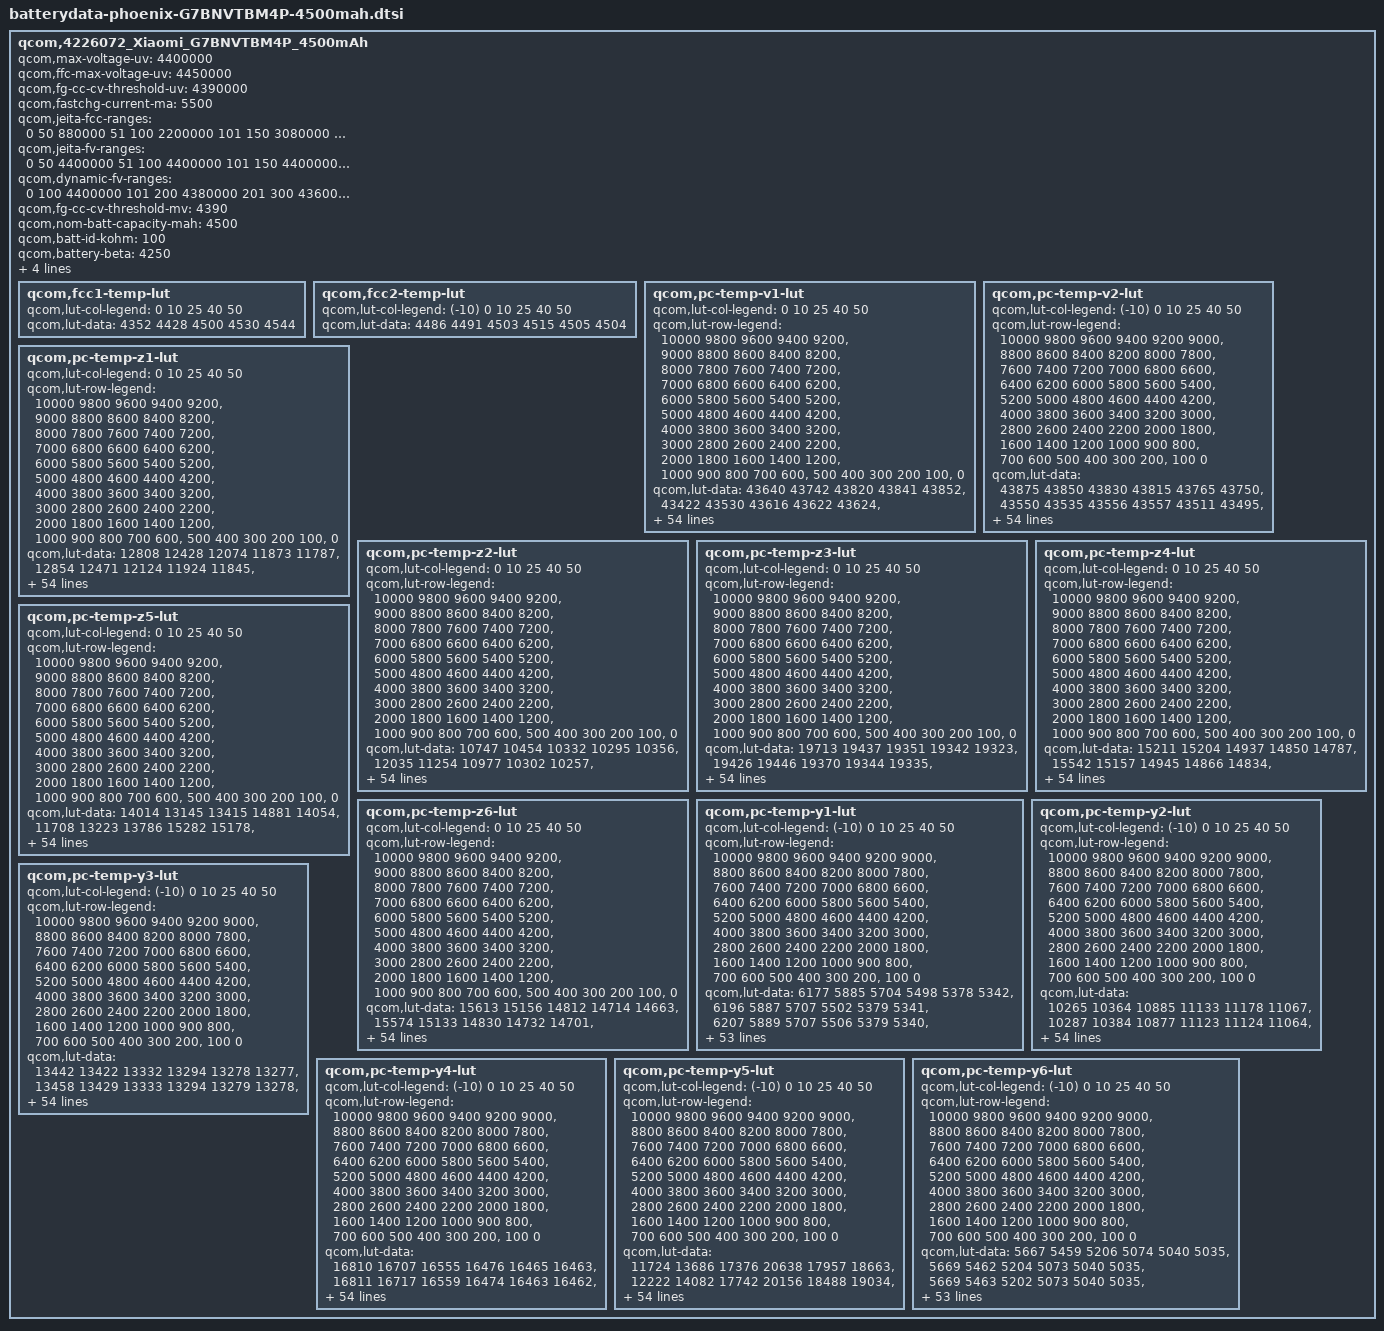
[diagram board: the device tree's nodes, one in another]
qcom,4226072_Xiaomi_G7BNVTBM4P_4500mAh {
    /* 4226072_Xiaomi_G7BNVTBM4P_4500mAh_averaged_MasterSlave_Sept30th2019 */
	qcom,max-voltage-uv = <4400000>;
	qcom,ffc-max-voltage-uv = <4450000>;
	qcom,fg-cc-cv-threshold-uv = <4390000>;
	qcom,fastchg-current-ma = <5500>;
	qcom,jeita-fcc-ranges = <0  50  880000
				51  100  2200000
				101 150  3080000
				151 450  5500000
				451 580  2200000>;
	qcom,jeita-fv-ranges = <0   50  4400000
				51  100  4400000
				101 150  4400000
				151 450  4450000
				451 580  4100000>;
	qcom,dynamic-fv-ranges = <0    100  4400000
				101  200  4380000
				201  300  4360000
				301  400  4340000
				401  500  4340000>;
	qcom,fg-cc-cv-threshold-mv = <4390>;
	qcom,nom-batt-capacity-mah = <4500>;
	qcom,batt-id-kohm = <100>;
	qcom,battery-beta = <4250>;
	qcom,battery-therm-kohm = <100>;
	qcom,battery-type = "G7BNVTBM4P_4500mAh";
	qcom,qg-batt-profile-ver = <100>;
	mi,six-pin-battery;

	qcom,fcc1-temp-lut {
		qcom,lut-col-legend = <0 10 25 40 50>;
		qcom,lut-data = <4352 4428 4500 4530 4544>;
	};

	qcom,fcc2-temp-lut {
		qcom,lut-col-legend = <(-10) 0 10 25 40 50>;
		qcom,lut-data = <4486 4491 4503 4515 4505 4504>;
	};

	qcom,pc-temp-v1-lut {
		qcom,lut-col-legend = <0 10 25 40 50>;
		qcom,lut-row-legend = <10000 9800 9600 9400 9200>,
			<9000 8800 8600 8400 8200>,
			<8000 7800 7600 7400 7200>,
			<7000 6800 6600 6400 6200>,
			<6000 5800 5600 5400 5200>,
			<5000 4800 4600 4400 4200>,
			<4000 3800 3600 3400 3200>,
			<3000 2800 2600 2400 2200>,
			<2000 1800 1600 1400 1200>,
			<1000 900 800 700 600>,
			<500 400 300 200 100>,
			<0>;
		qcom,lut-data = <43640 43742 43820 43841 43852>,
			<43422 43530 43616 43622 43624>,
			<43175 43306 43394 43399 43404>,
			<42915 43069 43166 43176 43182>,
			<42670 42828 42929 42949 42955>,
			<42438 42586 42689 42720 42725>,
			<42211 42344 42451 42488 42495>,
			<41991 42111 42212 42252 42264>,
			<41775 41892 41981 42021 42035>,
			<41566 41679 41756 41793 41808>,
			<41363 41465 41535 41570 41582>,
			<41165 41250 41319 41352 41360>,
			<40972 41045 41105 41137 41141>,
			<40784 40858 40903 40931 40930>,
			<40581 40674 40709 40729 40727>,
			<40345 40470 40518 40533 40532>,
			<40111 40243 40319 40340 40342>,
			<39938 40042 40124 40152 40157>,
			<39802 39899 39954 39976 39982>,
			<39668 39771 39813 39823 39827>,
			<39531 39595 39654 39663 39667>,
			<39387 39345 39413 39446 39459>,
			<39210 39114 39144 39190 39203>,
			<38965 38952 38963 38993 39000>,
			<38758 38817 38839 38854 38856>,
			<38656 38713 38731 38736 38734>,
			<38585 38631 38630 38624 38620>,
			<38522 38560 38539 38521 38516>,
			<38464 38485 38453 38429 38423>,
			<38412 38414 38372 38344 38336>,
			<38362 38351 38299 38268 38258>,
			<38315 38294 38235 38198 38186>,
			<38272 38243 38179 38136 38122>,
			<38235 38197 38129 38079 38060>,
			<38202 38158 38086 38030 38005>,
			<38170 38120 38044 37982 37950>,
			<38142 38088 38004 37931 37889>,
			<38106 38052 37962 37877 37825>,
			<38047 37993 37903 37809 37748>,
			<37962 37904 37816 37722 37655>,
			<37866 37802 37715 37620 37550>,
			<37749 37688 37603 37509 37438>,
			<37613 37554 37474 37381 37310>,
			<37449 37388 37310 37220 37143>,
			<37302 37239 37166 37081 37012>,
			<37213 37142 37070 36993 36935>,
			<37184 37119 37043 36968 36911>,
			<37166 37098 37029 36949 36893>,
			<37147 37080 37012 36932 36875>,
			<37109 37045 36973 36884 36817>,
			<36927 36846 36755 36642 36546>,
			<36488 36410 36323 36210 36109>,
			<35916 35838 35748 35643 35536>,
			<35138 35054 34964 34858 34753>,
			<33901 33819 33742 33654 33539>,
			<30000 30000 30000 30000 30000>;
	};

	qcom,pc-temp-v2-lut {
		qcom,lut-col-legend = <(-10) 0 10 25 40 50>;
		qcom,lut-row-legend = <10000 9800 9600 9400 9200 9000>,
			<8800 8600 8400 8200 8000 7800>,
			<7600 7400 7200 7000 6800 6600>,
			<6400 6200 6000 5800 5600 5400>,
			<5200 5000 4800 4600 4400 4200>,
			<4000 3800 3600 3400 3200 3000>,
			<2800 2600 2400 2200 2000 1800>,
			<1600 1400 1200 1000 900 800>,
			<700 600 500 400 300 200>,
			<100 0>;
		qcom,lut-data = <43875 43850 43830 43815 43765 43750>,
			<43550 43535 43556 43557 43511 43495>,
			<43246 43239 43292 43305 43263 43247>,
			<42968 42966 43037 43060 43022 43006>,
			<42714 42715 42793 42823 42789 42775>,
			<42469 42470 42552 42587 42557 42544>,
			<42227 42225 42314 42352 42323 42311>,
			<41991 41984 42078 42118 42089 42078>,
			<41759 41746 41847 41888 41860 41849>,
			<41530 41507 41620 41662 41633 41622>,
			<41312 41285 41398 41438 41409 41398>,
			<41121 41093 41186 41217 41189 41178>,
			<40938 40912 40978 40999 40973 40963>,
			<40724 40704 40771 40793 40766 40756>,
			<40473 40469 40565 40596 40567 40553>,
			<40205 40233 40361 40400 40372 40359>,
			<39903 40007 40160 40194 40178 40173>,
			<39599 39788 39963 39993 39991 39994>,
			<39387 39583 39771 39822 39821 39825>,
			<39239 39390 39585 39678 39673 39670>,
			<39101 39202 39391 39512 39505 39497>,
			<38953 39008 39167 39271 39270 39266>,
			<38805 38820 38942 39013 39018 39019>,
			<38654 38663 38767 38822 38829 38832>,
			<38494 38528 38624 38667 38678 38681>,
			<38358 38405 38498 38536 38549 38552>,
			<38264 38281 38385 38423 38436 38438>,
			<38188 38169 38284 38324 38336 38337>,
			<38119 38089 38192 38234 38244 38244>,
			<38056 38030 38107 38151 38159 38157>,
			<38000 37981 38031 38075 38082 38079>,
			<37949 37936 37957 38003 38014 38011>,
			<37901 37895 37892 37937 37951 37947>,
			<37854 37859 37846 37876 37886 37879>,
			<37808 37829 37814 37822 37822 37809>,
			<37762 37795 37779 37765 37749 37728>,
			<37713 37751 37740 37702 37655 37619>,
			<37662 37697 37696 37634 37552 37500>,
			<37604 37637 37638 37561 37464 37407>,
			<37540 37568 37563 37483 37387 37332>,
			<37466 37487 37474 37396 37306 37252>,
			<37369 37381 37366 37298 37217 37160>,
			<37255 37253 37241 37186 37114 37053>,
			<37143 37103 37094 37047 36972 36913>,
			<37044 36963 36963 36928 36862 36801>,
			<36963 36870 36890 36871 36816 36761>,
			<36925 36835 36866 36860 36803 36753>,
			<36885 36802 36844 36840 36790 36739>,
			<36837 36755 36808 36813 36768 36711>,
			<36762 36674 36733 36736 36690 36619>,
			<36577 36475 36510 36463 36397 36289>,
			<36182 36065 36016 35953 35905 35790>,
			<35582 35458 35364 35300 35268 35139>,
			<34732 34607 34479 34393 34394 34261>,
			<33365 33219 33123 33054 33081 32922>,
			<28583 28570 28114 28120 28771 28597>;
	};

	qcom,pc-temp-z1-lut {
		qcom,lut-col-legend = <0 10 25 40 50>;
		qcom,lut-row-legend = <10000 9800 9600 9400 9200>,
			<9000 8800 8600 8400 8200>,
			<8000 7800 7600 7400 7200>,
			<7000 6800 6600 6400 6200>,
			<6000 5800 5600 5400 5200>,
			<5000 4800 4600 4400 4200>,
			<4000 3800 3600 3400 3200>,
			<3000 2800 2600 2400 2200>,
			<2000 1800 1600 1400 1200>,
			<1000 900 800 700 600>,
			<500 400 300 200 100>,
			<0>;
		qcom,lut-data = <12808 12428 12074 11873 11787>,
			<12854 12471 12124 11924 11845>,
			<12866 12489 12146 11939 11859>,
			<12869 12487 12150 11943 11865>,
			<12865 12482 12146 11941 11866>,
			<12856 12478 12142 11938 11866>,
			<12850 12471 12137 11935 11865>,
			<12853 12465 12133 11932 11865>,
			<12861 12459 12130 11931 11864>,
			<12862 12452 12126 11930 11865>,
			<12845 12447 12124 11930 11866>,
			<12822 12438 12123 11930 11866>,
			<12807 12431 12121 11932 11866>,
			<12791 12425 12119 11932 11866>,
			<12775 12416 12116 11929 11866>,
			<12756 12409 12113 11927 11866>,
			<12742 12401 12112 11927 11866>,
			<12743 12398 12111 11928 11867>,
			<12755 12403 12111 11929 11868>,
			<12763 12413 12115 11931 11869>,
			<12763 12417 12119 11932 11870>,
			<12762 12421 12122 11932 11871>,
			<12764 12423 12124 11932 11871>,
			<12773 12423 12126 11932 11872>,
			<12781 12422 12128 11935 11874>,
			<12783 12424 12130 11938 11877>,
			<12785 12430 12133 11942 11880>,
			<12784 12436 12138 11945 11883>,
			<12781 12438 12142 11948 11886>,
			<12778 12439 12145 11952 11889>,
			<12782 12439 12149 11955 11892>,
			<12796 12438 12152 11959 11895>,
			<12804 12438 12154 11964 11898>,
			<12805 12442 12158 11968 11901>,
			<12805 12451 12163 11972 11906>,
			<12810 12459 12169 11976 11910>,
			<12824 12466 12173 11980 11913>,
			<12838 12474 12177 11984 11916>,
			<12851 12483 12181 11989 11919>,
			<12863 12494 12187 11993 11922>,
			<12871 12500 12192 11998 11924>,
			<12877 12502 12196 12000 11927>,
			<12879 12503 12199 12003 11930>,
			<12878 12506 12202 12004 11931>,
			<12891 12512 12206 12006 11932>,
			<12888 12517 12210 12010 11933>,
			<12902 12510 12203 12008 11934>,
			<12896 12526 12217 12008 11935>,
			<12890 12514 12223 12012 11938>,
			<12888 12512 12222 12016 11942>,
			<12896 12523 12222 12022 11946>,
			<12917 12534 12245 12030 11952>,
			<12925 12542 12242 12036 11959>,
			<12932 12567 12252 12045 11970>,
			<12932 12567 12252 12045 11970>,
			<12932 12567 12252 12045 11970>;
	};

	qcom,pc-temp-z2-lut {
		qcom,lut-col-legend = <0 10 25 40 50>;
		qcom,lut-row-legend = <10000 9800 9600 9400 9200>,
			<9000 8800 8600 8400 8200>,
			<8000 7800 7600 7400 7200>,
			<7000 6800 6600 6400 6200>,
			<6000 5800 5600 5400 5200>,
			<5000 4800 4600 4400 4200>,
			<4000 3800 3600 3400 3200>,
			<3000 2800 2600 2400 2200>,
			<2000 1800 1600 1400 1200>,
			<1000 900 800 700 600>,
			<500 400 300 200 100>,
			<0>;
		qcom,lut-data = <10747 10454 10332 10295 10356>,
			<12035 11254 10977 10302 10257>,
			<11377 11491 11701 10333 10304>,
			<10414 11301 11844 10407 10339>,
			<10189 11007 11692 11167 10328>,
			<10174 10722 11464 12039 10309>,
			<10166 10410 11026 11823 10293>,
			<10160 10287 10503 10810 10249>,
			<10155 10353 10369 10358 10217>,
			<10154 10424 10351 10737 10207>,
			<10158 10403 10344 11128 10199>,
			<10166 10321 10351 11246 10200>,
			<10198 10285 10371 11595 10208>,
			<10269 10449 10466 11795 10214>,
			<10301 10680 10882 11846 10224>,
			<10266 10683 11187 11904 10236>,
			<10221 10490 11223 11983 10242>,
			<10221 10362 11242 12080 10257>,
			<10251 10377 11170 12062 10273>,
			<10277 10402 10730 11211 10302>,
			<10289 10408 10424 10364 10347>,
			<10298 10409 10450 10361 10419>,
			<10299 10408 10497 10482 10536>,
			<10293 10398 10503 10522 10619>,
			<10289 10379 10476 10466 10670>,
			<10290 10374 10456 10411 10700>,
			<10295 10381 10459 10418 10651>,
			<10299 10388 10466 10440 10489>,
			<10306 10387 10465 10441 10367>,
			<10313 10386 10451 10373 10245>,
			<10321 10387 10440 10302 10154>,
			<10332 10393 10440 10277 10152>,
			<10343 10402 10440 10261 10158>,
			<10357 10413 10443 10259 10169>,
			<10372 10428 10462 10274 10211>,
			<10386 10441 10483 10297 10268>,
			<10399 10450 10497 10335 10323>,
			<10412 10461 10512 10388 10381>,
			<10425 10477 10533 10426 10419>,
			<10439 10500 10565 10455 10447>,
			<10452 10511 10586 10471 10461>,
			<10461 10513 10584 10471 10451>,
			<10477 10516 10580 10466 10431>,
			<10510 10529 10592 10457 10417>,
			<10732 10661 10625 10457 10400>,
			<10904 10730 10649 10477 10394>,
			<10942 10745 10635 10508 10385>,
			<11078 10756 10638 10486 10394>,
			<11243 10780 10620 10524 10475>,
			<11235 10785 10669 10583 10575>,
			<11217 10889 10753 10476 10370>,
			<11047 10885 10729 10338 10190>,
			<10878 10897 10625 10849 10140>,
			<10658 10857 10599 10243 10085>,
			<10658 10857 10599 10243 10085>,
			<10658 10857 10599 10243 10085>;
	};

	qcom,pc-temp-z3-lut {
		qcom,lut-col-legend = <0 10 25 40 50>;
		qcom,lut-row-legend = <10000 9800 9600 9400 9200>,
			<9000 8800 8600 8400 8200>,
			<8000 7800 7600 7400 7200>,
			<7000 6800 6600 6400 6200>,
			<6000 5800 5600 5400 5200>,
			<5000 4800 4600 4400 4200>,
			<4000 3800 3600 3400 3200>,
			<3000 2800 2600 2400 2200>,
			<2000 1800 1600 1400 1200>,
			<1000 900 800 700 600>,
			<500 400 300 200 100>,
			<0>;
		qcom,lut-data = <19713 19437 19351 19342 19323>,
			<19426 19446 19370 19344 19335>,
			<19524 19464 19395 19364 19353>,
			<19668 19508 19419 19382 19369>,
			<19704 19550 19447 19402 19377>,
			<19709 19556 19462 19417 19383>,
			<19711 19557 19457 19414 19384>,
			<19705 19559 19448 19401 19385>,
			<19692 19558 19444 19395 19384>,
			<19680 19554 19442 19402 19382>,
			<19669 19549 19440 19410 19380>,
			<19662 19539 19436 19411 19378>,
			<19667 19534 19431 19412 19376>,
			<19683 19539 19432 19412 19374>,
			<19689 19545 19445 19409 19369>,
			<19679 19544 19453 19406 19362>,
			<19662 19530 19453 19403 19359>,
			<19647 19515 19450 19400 19358>,
			<19631 19500 19444 19394 19355>,
			<19623 19487 19422 19374 19349>,
			<19625 19488 19407 19357 19343>,
			<19631 19512 19413 19359 19345>,
			<19639 19530 19424 19368 19353>,
			<19653 19525 19424 19371 19361>,
			<19662 19514 19411 19364 19371>,
			<19659 19509 19402 19358 19380>,
			<19651 19507 19409 19369 19386>,
			<19643 19506 19422 19396 19396>,
			<19635 19510 19431 19404 19399>,
			<19628 19519 19439 19401 19393>,
			<19623 19521 19443 19397 19384>,
			<19620 19519 19441 19393 19378>,
			<19616 19517 19436 19388 19372>,
			<19611 19514 19431 19382 19365>,
			<19606 19511 19426 19376 19356>,
			<19603 19508 19422 19370 19350>,
			<19600 19504 19417 19366 19349>,
			<19597 19500 19413 19363 19348>,
			<19596 19497 19410 19361 19348>,
			<19593 19494 19408 19360 19348>,
			<19590 19490 19405 19359 19348>,
			<19583 19484 19400 19359 19349>,
			<19576 19478 19395 19358 19351>,
			<19567 19475 19395 19360 19357>,
			<19511 19451 19385 19359 19356>,
			<19461 19437 19376 19349 19348>,
			<19444 19422 19376 19338 19336>,
			<19381 19421 19361 19338 19330>,
			<19322 19416 19360 19333 19321>,
			<19316 19412 19355 19331 19315>,
			<19322 19400 19350 19347 19344>,
			<19321 19393 19347 19355 19351>,
			<19319 19351 19356 19310 19351>,
			<19319 19342 19355 19359 19355>,
			<19319 19342 19355 19359 19355>,
			<19319 19342 19355 19359 19355>;
	};

	qcom,pc-temp-z4-lut {
		qcom,lut-col-legend = <0 10 25 40 50>;
		qcom,lut-row-legend = <10000 9800 9600 9400 9200>,
			<9000 8800 8600 8400 8200>,
			<8000 7800 7600 7400 7200>,
			<7000 6800 6600 6400 6200>,
			<6000 5800 5600 5400 5200>,
			<5000 4800 4600 4400 4200>,
			<4000 3800 3600 3400 3200>,
			<3000 2800 2600 2400 2200>,
			<2000 1800 1600 1400 1200>,
			<1000 900 800 700 600>,
			<500 400 300 200 100>,
			<0>;
		qcom,lut-data = <15211 15204 14937 14850 14787>,
			<15542 15157 14945 14866 14834>,
			<15447 15095 14910 14857 14829>,
			<15276 15004 14871 14842 14821>,
			<15158 14918 14821 14796 14807>,
			<15068 14877 14789 14750 14787>,
			<14999 14853 14782 14746 14770>,
			<14952 14826 14777 14751 14757>,
			<14916 14788 14768 14752 14744>,
			<14887 14757 14750 14725 14731>,
			<14866 14748 14733 14693 14719>,
			<14843 14744 14723 14680 14712>,
			<14803 14738 14714 14665 14707>,
			<14747 14708 14699 14656 14703>,
			<14725 14673 14670 14648 14700>,
			<14742 14673 14649 14642 14697>,
			<14764 14703 14643 14639 14693>,
			<14765 14723 14640 14636 14688>,
			<14754 14716 14640 14636 14683>,
			<14743 14705 14651 14648 14679>,
			<14732 14708 14669 14669 14677>,
			<14723 14749 14719 14708 14696>,
			<14729 14790 14786 14766 14756>,
			<14792 14812 14806 14789 14783>,
			<14845 14829 14812 14793 14770>,
			<14843 14830 14814 14794 14751>,
			<14831 14812 14798 14777 14733>,
			<14819 14789 14765 14732 14710>,
			<14805 14769 14741 14709 14699>,
			<14790 14748 14721 14702 14695>,
			<14777 14735 14708 14696 14693>,
			<14764 14726 14702 14691 14689>,
			<14753 14720 14698 14687 14685>,
			<14743 14716 14695 14685 14682>,
			<14736 14714 14693 14683 14680>,
			<14729 14711 14692 14682 14679>,
			<14722 14707 14690 14682 14680>,
			<14718 14705 14689 14683 14681>,
			<14718 14706 14690 14685 14684>,
			<14718 14709 14695 14692 14692>,
			<14718 14710 14699 14697 14697>,
			<14716 14706 14695 14691 14690>,
			<14712 14701 14690 14683 14681>,
			<14707 14697 14688 14684 14684>,
			<14699 14683 14681 14675 14676>,
			<14716 14672 14669 14664 14656>,
			<14730 14678 14660 14665 14657>,
			<14795 14671 14664 14651 14649>,
			<14856 14670 14654 14637 14637>,
			<14861 14672 14656 14632 14632>,
			<14854 14692 14679 14647 14644>,
			<14869 14709 14692 14651 14650>,
			<14880 14760 14685 14703 14655>,
			<14888 14774 14690 14655 14653>,
			<14888 14774 14690 14655 14653>,
			<14888 14774 14690 14655 14653>;
	};

	qcom,pc-temp-z5-lut {
		qcom,lut-col-legend = <0 10 25 40 50>;
		qcom,lut-row-legend = <10000 9800 9600 9400 9200>,
			<9000 8800 8600 8400 8200>,
			<8000 7800 7600 7400 7200>,
			<7000 6800 6600 6400 6200>,
			<6000 5800 5600 5400 5200>,
			<5000 4800 4600 4400 4200>,
			<4000 3800 3600 3400 3200>,
			<3000 2800 2600 2400 2200>,
			<2000 1800 1600 1400 1200>,
			<1000 900 800 700 600>,
			<500 400 300 200 100>,
			<0>;
		qcom,lut-data = <14014 13145 13415 14881 14054>,
			<11708 13223 13786 15282 15178>,
			<12922 13461 14612 16708 16823>,
			<14963 14601 15761 18189 18427>,
			<16109 16256 17687 20060 19273>,
			<16847 17757 19158 21539 19930>,
			<17286 19340 19655 21405 20387>,
			<17408 20462 19997 20508 20723>,
			<17477 21129 20482 20294 21068>,
			<17593 21674 21152 24126 21539>,
			<17863 22160 21911 28275 22120>,
			<18348 22720 22661 29120 22788>,
			<20007 23659 23593 30310 23599>,
			<23496 27225 25474 31883 23950>,
			<25443 31507 29900 34241 23536>,
			<25823 31751 33843 36580 23003>,
			<25939 28990 36080 38102 23340>,
			<25556 26426 37660 39361 24832>,
			<24466 25042 37160 39382 25727>,
			<23855 24054 32567 33413 25852>,
			<26098 26299 29333 27401 25894>,
			<31014 41133 31330 27005 26063>,
			<36242 52201 34705 27134 26288>,
			<43241 45706 34000 26702 26194>,
			<47788 32512 25575 21763 23585>,
			<44940 26830 19740 17189 20882>,
			<37505 24863 20161 18466 21872>,
			<32764 23963 21321 22345 25112>,
			<30373 25104 23253 25043 26731>,
			<28971 28250 27524 26561 27144>,
			<28991 30860 31487 27908 27417>,
			<29595 33080 33899 29579 27821>,
			<30241 34964 35771 31226 28413>,
			<30770 36341 36946 31964 28592>,
			<31289 37505 37865 32318 28266>,
			<31852 37840 38278 32485 28081>,
			<32711 37184 37469 32323 28843>,
			<33301 36145 35673 31816 30141>,
			<33876 35265 33880 30983 30290>,
			<34762 34351 31873 28998 28188>,
			<34644 33108 29770 27036 26461>,
			<32209 30496 27219 25723 26468>,
			<31160 28956 25491 24962 26609>,
			<31632 28851 25376 25699 29848>,
			<29221 29016 24634 25841 30655>,
			<21264 28617 23788 22922 26044>,
			<19785 23338 24702 19390 20317>,
			<15905 23586 20085 20858 20128>,
			<12633 22677 20812 22708 20900>,
			<12518 21795 19973 23282 20706>,
			<12749 18911 17324 23007 26231>,
			<12554 17226 15903 21886 23496>,
			<12372 13965 16607 16263 20868>,
			<12228 13384 16017 19628 19562>,
			<12228 13384 16017 19628 19562>,
			<12228 13384 16017 19628 19562>;
	};

	qcom,pc-temp-z6-lut {
		qcom,lut-col-legend = <0 10 25 40 50>;
		qcom,lut-row-legend = <10000 9800 9600 9400 9200>,
			<9000 8800 8600 8400 8200>,
			<8000 7800 7600 7400 7200>,
			<7000 6800 6600 6400 6200>,
			<6000 5800 5600 5400 5200>,
			<5000 4800 4600 4400 4200>,
			<4000 3800 3600 3400 3200>,
			<3000 2800 2600 2400 2200>,
			<2000 1800 1600 1400 1200>,
			<1000 900 800 700 600>,
			<500 400 300 200 100>,
			<0>;
		qcom,lut-data = <15613 15156 14812 14714 14663>,
			<15574 15133 14830 14732 14701>,
			<15540 15108 14831 14741 14711>,
			<15505 15078 14830 14743 14714>,
			<15460 15049 14821 14737 14712>,
			<15400 15025 14810 14727 14708>,
			<15345 15004 14801 14721 14703>,
			<15304 14984 14792 14716 14697>,
			<15269 14961 14783 14710 14691>,
			<15239 14941 14773 14703 14685>,
			<15214 14927 14764 14695 14679>,
			<15191 14918 14757 14689 14674>,
			<15162 14908 14750 14685 14671>,
			<15131 14891 14744 14680 14668>,
			<15113 14876 14738 14675 14663>,
			<15106 14874 14734 14671 14658>,
			<15100 14876 14730 14667 14655>,
			<15092 14877 14728 14665 14652>,
			<15080 14870 14724 14662 14648>,
			<15074 14859 14719 14657 14643>,
			<15075 14861 14716 14654 14639>,
			<15078 14892 14739 14667 14648>,
			<15087 14919 14776 14699 14679>,
			<15122 14925 14784 14711 14693>,
			<15150 14929 14782 14710 14693>,
			<15149 14929 14779 14709 14692>,
			<15141 14921 14775 14707 14690>,
			<15134 14913 14770 14703 14686>,
			<15126 14908 14766 14699 14682>,
			<15118 14904 14763 14695 14677>,
			<15111 14901 14760 14691 14673>,
			<15106 14898 14757 14687 14668>,
			<15102 14895 14753 14683 14664>,
			<15098 14894 14751 14679 14659>,
			<15095 14894 14748 14675 14654>,
			<15095 14893 14746 14672 14651>,
			<15096 14893 14744 14671 14650>,
			<15097 14893 14743 14669 14650>,
			<15101 14894 14743 14670 14650>,
			<15108 14898 14746 14672 14654>,
			<15113 14900 14747 14674 14657>,
			<15116 14899 14744 14672 14655>,
			<15120 14898 14741 14669 14652>,
			<15124 14899 14742 14671 14656>,
			<15105 14889 14736 14667 14653>,
			<15092 14880 14727 14657 14640>,
			<15090 14875 14724 14653 14635>,
			<15088 14872 14718 14646 14628>,
			<15086 14871 14713 14638 14618>,
			<15089 14874 14714 14635 14613>,
			<15098 14881 14724 14651 14635>,
			<15109 14890 14731 14660 14644>,
			<15123 14896 14735 14663 14649>,
			<15142 14907 14741 14668 14653>,
			<15142 14907 14741 14668 14653>,
			<15142 14907 14741 14668 14653>;
	};

	qcom,pc-temp-y1-lut {
		qcom,lut-col-legend = <(-10) 0 10 25 40 50>;
		qcom,lut-row-legend = <10000 9800 9600 9400 9200 9000>,
			<8800 8600 8400 8200 8000 7800>,
			<7600 7400 7200 7000 6800 6600>,
			<6400 6200 6000 5800 5600 5400>,
			<5200 5000 4800 4600 4400 4200>,
			<4000 3800 3600 3400 3200 3000>,
			<2800 2600 2400 2200 2000 1800>,
			<1600 1400 1200 1000 900 800>,
			<700 600 500 400 300 200>,
			<100 0>;
		qcom,lut-data = <6177 5885 5704 5498 5378 5342>,
			<6196 5887 5707 5502 5379 5341>,
			<6207 5889 5707 5506 5379 5340>,
			<6212 5890 5705 5508 5379 5339>,
			<6213 5890 5703 5508 5379 5339>,
			<6210 5889 5702 5508 5379 5338>,
			<6201 5887 5699 5505 5378 5337>,
			<6188 5885 5696 5502 5376 5337>,
			<6183 5884 5695 5500 5375 5336>,
			<6179 5883 5692 5498 5373 5335>,
			<6178 5883 5690 5497 5372 5335>,
			<6180 5882 5687 5496 5372 5334>,
			<6184 5881 5685 5496 5372 5334>,
			<6189 5883 5686 5496 5371 5334>,
			<6200 5888 5691 5497 5370 5333>,
			<6207 5892 5694 5498 5370 5333>,
			<6206 5895 5693 5497 5371 5333>,
			<6205 5898 5690 5497 5372 5333>,
			<6203 5899 5687 5497 5372 5334>,
			<6201 5900 5684 5499 5371 5334>,
			<6199 5900 5683 5501 5371 5335>,
			<6200 5899 5685 5501 5371 5335>,
			<6200 5897 5689 5501 5372 5335>,
			<6201 5896 5690 5501 5374 5336>,
			<6207 5893 5690 5502 5375 5337>,
			<6210 5892 5690 5503 5377 5339>,
			<6203 5897 5690 5505 5378 5340>,
			<6193 5907 5690 5508 5380 5342>,
			<6191 5908 5691 5512 5382 5344>,
			<6194 5900 5692 5516 5384 5345>,
			<6196 5893 5694 5518 5386 5347>,
			<6193 5891 5698 5519 5389 5348>,
			<6188 5889 5701 5519 5391 5350>,
			<6186 5888 5701 5521 5393 5351>,
			<6181 5886 5697 5524 5393 5353>,
			<6176 5883 5695 5526 5394 5355>,
			<6172 5879 5695 5526 5395 5356>,
			<6165 5874 5695 5526 5397 5356>,
			<6159 5873 5695 5527 5397 5357>,
			<6152 5876 5691 5530 5396 5358>,
			<6148 5879 5688 5531 5396 5358>,
			<6149 5876 5690 5532 5397 5359>,
			<6152 5873 5695 5533 5399 5360>,
			<6158 5870 5701 5535 5402 5363>,
			<6159 5872 5711 5544 5406 5367>,
			<6175 5898 5714 5551 5412 5369>,
			<6198 5903 5717 5550 5412 5369>,
			<6203 5882 5723 5550 5412 5368>,
			<6193 5894 5718 5551 5411 5369>,
			<6193 5894 5720 5554 5412 5370>,
			<6204 5899 5718 5555 5415 5372>,
			<6216 5911 5725 5556 5418 5375>,
			<6206 5917 5734 5567 5422 5380>,
			<6229 5924 5739 5580 5429 5385>,
			<6229 5924 5739 5580 5429 5385>,
			<6229 5924 5739 5580 5429 5385>;
	};

	qcom,pc-temp-y2-lut {
		qcom,lut-col-legend = <(-10) 0 10 25 40 50>;
		qcom,lut-row-legend = <10000 9800 9600 9400 9200 9000>,
			<8800 8600 8400 8200 8000 7800>,
			<7600 7400 7200 7000 6800 6600>,
			<6400 6200 6000 5800 5600 5400>,
			<5200 5000 4800 4600 4400 4200>,
			<4000 3800 3600 3400 3200 3000>,
			<2800 2600 2400 2200 2000 1800>,
			<1600 1400 1200 1000 900 800>,
			<700 600 500 400 300 200>,
			<100 0>;
		qcom,lut-data = <10265 10364 10885 11133 11178 11067>,
			<10287 10384 10877 11123 11124 11064>,
			<10309 10403 10866 11108 11066 11047>,
			<10331 10421 10854 11089 11011 11023>,
			<10349 10437 10841 11068 10964 10994>,
			<10362 10452 10828 11046 10932 10964>,
			<10369 10467 10813 11017 10912 10925>,
			<10375 10480 10798 10989 10898 10884>,
			<10389 10481 10791 10979 10890 10868>,
			<10428 10473 10788 10977 10887 10863>,
			<10485 10467 10784 10977 10881 10861>,
			<10601 10571 10780 10971 10860 10861>,
			<10735 10739 10775 10962 10835 10860>,
			<10763 10776 10790 10960 10830 10856>,
			<10763 10776 10874 10961 10834 10838>,
			<10763 10777 10955 10962 10843 10827>,
			<10780 10806 10997 10999 10883 10839>,
			<10818 10862 11031 11068 10955 10865>,
			<10861 10907 11064 11142 11034 10900>,
			<10920 10946 11096 11233 11137 10970>,
			<10958 10986 11119 11275 11189 11034>,
			<10963 11038 11130 11257 11168 11079>,
			<10965 11087 11139 11231 11135 11116>,
			<10967 11094 11156 11227 11123 11132>,
			<10968 11079 11182 11238 11116 11137>,
			<10967 11050 11212 11252 11114 11142>,
			<10600 10720 11244 11277 11126 11153>,
			<9942 10194 11275 11310 11152 11167>,
			<9756 10099 11289 11337 11183 11186>,
			<9736 10352 11297 11362 11232 11214>,
			<9723 10551 11304 11382 11267 11243>,
			<9711 10696 11312 11397 11284 11278>,
			<9701 10909 11319 11409 11296 11309>,
			<9695 10930 11315 11417 11296 11313>,
			<9691 10889 11286 11425 11287 11304>,
			<9687 10820 11254 11427 11274 11290>,
			<9684 10471 11225 11406 11250 11248>,
			<9681 9940 11192 11371 11217 11190>,
			<9678 9768 11152 11342 11187 11156>,
			<9676 9727 11102 11313 11155 11122>,
			<9674 9704 11050 11287 11136 11101>,
			<9672 9690 10996 11264 11138 11108>,
			<9670 9681 10932 11245 11144 11111>,
			<9668 9674 10837 11232 11141 11057>,
			<9665 9669 10752 11154 11067 10966>,
			<9664 9665 10674 11092 10951 10801>,
			<9663 9663 10623 11115 10943 10810>,
			<9662 9662 10582 11099 10929 10825>,
			<9661 9660 10550 11098 11004 10794>,
			<9660 9659 10514 11102 10997 10799>,
			<9658 9657 10421 11057 10936 10809>,
			<9657 9656 9971 10968 10867 10730>,
			<9655 9655 9751 10902 10769 10653>,
			<9652 9654 9686 10803 10699 10540>,
			<9652 9654 9686 10803 10699 10540>,
			<9652 9654 9686 10803 10699 10540>;
	};

	qcom,pc-temp-y3-lut {
		qcom,lut-col-legend = <(-10) 0 10 25 40 50>;
		qcom,lut-row-legend = <10000 9800 9600 9400 9200 9000>,
			<8800 8600 8400 8200 8000 7800>,
			<7600 7400 7200 7000 6800 6600>,
			<6400 6200 6000 5800 5600 5400>,
			<5200 5000 4800 4600 4400 4200>,
			<4000 3800 3600 3400 3200 3000>,
			<2800 2600 2400 2200 2000 1800>,
			<1600 1400 1200 1000 900 800>,
			<700 600 500 400 300 200>,
			<100 0>;
		qcom,lut-data = <13442 13422 13332 13294 13278 13277>,
			<13458 13429 13333 13294 13279 13278>,
			<13473 13434 13334 13294 13280 13278>,
			<13484 13438 13336 13294 13281 13279>,
			<13491 13440 13337 13294 13282 13279>,
			<13494 13441 13338 13295 13282 13280>,
			<13490 13439 13339 13295 13283 13280>,
			<13485 13436 13340 13295 13283 13281>,
			<13486 13437 13340 13296 13283 13281>,
			<13501 13446 13341 13298 13284 13282>,
			<13511 13451 13342 13300 13285 13282>,
			<13487 13432 13344 13300 13285 13282>,
			<13447 13400 13345 13300 13286 13283>,
			<13440 13395 13346 13302 13286 13284>,
			<13449 13401 13345 13305 13287 13285>,
			<13455 13405 13343 13307 13288 13285>,
			<13441 13404 13341 13307 13290 13287>,
			<13417 13402 13338 13306 13292 13289>,
			<13405 13397 13336 13306 13292 13290>,
			<13401 13387 13335 13305 13293 13290>,
			<13397 13375 13333 13304 13293 13290>,
			<13392 13365 13328 13302 13289 13286>,
			<13387 13355 13321 13298 13284 13280>,
			<13378 13349 13318 13295 13282 13278>,
			<13361 13346 13315 13292 13281 13278>,
			<13349 13341 13313 13290 13281 13278>,
			<13350 13312 13312 13289 13280 13278>,
			<13354 13271 13310 13289 13280 13278>,
			<13356 13265 13310 13289 13280 13278>,
			<13359 13281 13309 13290 13279 13277>,
			<13362 13294 13309 13290 13278 13277>,
			<13369 13306 13306 13290 13279 13277>,
			<13377 13325 13303 13290 13279 13277>,
			<13386 13331 13304 13290 13280 13278>,
			<13393 13335 13306 13291 13281 13279>,
			<13402 13340 13309 13291 13282 13280>,
			<13413 13344 13310 13291 13281 13279>,
			<13425 13348 13311 13290 13279 13278>,
			<13440 13356 13312 13290 13279 13278>,
			<13459 13369 13312 13290 13280 13280>,
			<13480 13384 13313 13290 13281 13281>,
			<13502 13396 13315 13291 13283 13282>,
			<13527 13412 13316 13291 13285 13282>,
			<13560 13438 13317 13292 13281 13280>,
			<13616 13490 13321 13293 13281 13279>,
			<13663 13540 13324 13290 13285 13284>,
			<13702 13587 13326 13296 13287 13287>,
			<13767 13657 13333 13298 13290 13289>,
			<13844 13737 13341 13305 13293 13289>,
			<13945 13837 13351 13308 13293 13289>,
			<14063 13934 13357 13305 13289 13285>,
			<14225 14038 13359 13304 13288 13285>,
			<14515 14179 13397 13311 13293 13289>,
			<15330 14360 13484 13321 13299 13297>,
			<15330 14360 13484 13321 13299 13297>,
			<15330 14360 13484 13321 13299 13297>;
	};

	qcom,pc-temp-y4-lut {
		qcom,lut-col-legend = <(-10) 0 10 25 40 50>;
		qcom,lut-row-legend = <10000 9800 9600 9400 9200 9000>,
			<8800 8600 8400 8200 8000 7800>,
			<7600 7400 7200 7000 6800 6600>,
			<6400 6200 6000 5800 5600 5400>,
			<5200 5000 4800 4600 4400 4200>,
			<4000 3800 3600 3400 3200 3000>,
			<2800 2600 2400 2200 2000 1800>,
			<1600 1400 1200 1000 900 800>,
			<700 600 500 400 300 200>,
			<100 0>;
		qcom,lut-data = <16810 16707 16555 16476 16465 16463>,
			<16811 16717 16559 16474 16463 16462>,
			<16816 16732 16562 16474 16461 16461>,
			<16823 16748 16564 16474 16460 16460>,
			<16832 16760 16566 16475 16460 16460>,
			<16843 16766 16566 16476 16460 16459>,
			<16860 16766 16565 16478 16461 16459>,
			<16877 16765 16564 16481 16462 16460>,
			<16875 16760 16564 16482 16463 16460>,
			<16846 16737 16568 16483 16465 16462>,
			<16826 16722 16572 16485 16467 16464>,
			<16907 16801 16575 16489 16470 16465>,
			<17039 16930 16580 16496 16474 16466>,
			<17056 16952 16594 16503 16479 16469>,
			<16985 16921 16634 16512 16484 16473>,
			<16901 16882 16669 16522 16490 16477>,
			<16822 16840 16688 16533 16494 16480>,
			<16750 16795 16702 16548 16498 16484>,
			<16731 16765 16700 16571 16511 16494>,
			<16727 16745 16678 16609 16543 16518>,
			<16723 16723 16649 16627 16561 16532>,
			<16705 16691 16600 16580 16537 16516>,
			<16676 16656 16545 16511 16495 16488>,
			<16655 16627 16524 16485 16475 16473>,
			<16634 16600 16514 16471 16463 16463>,
			<16623 16586 16510 16466 16458 16459>,
			<16636 16612 16509 16467 16459 16460>,
			<16663 16656 16508 16470 16461 16461>,
			<16677 16663 16507 16473 16464 16463>,
			<16684 16632 16504 16477 16471 16468>,
			<16690 16608 16501 16481 16478 16474>,
			<16693 16589 16500 16486 16487 16483>,
			<16696 16560 16499 16490 16496 16492>,
			<16699 16559 16500 16491 16497 16496>,
			<16704 16567 16508 16493 16497 16499>,
			<16710 16579 16517 16493 16497 16500>,
			<16716 16603 16526 16487 16482 16485>,
			<16723 16633 16534 16479 16461 16463>,
			<16726 16646 16536 16477 16459 16460>,
			<16727 16652 16536 16475 16461 16465>,
			<16726 16654 16537 16475 16464 16470>,
			<16716 16652 16538 16481 16469 16476>,
			<16703 16649 16541 16485 16473 16478>,
			<16702 16649 16546 16481 16461 16458>,
			<16705 16648 16547 16476 16451 16446>,
			<16705 16640 16539 16481 16454 16456>,
			<16712 16651 16550 16487 16472 16484>,
			<16727 16667 16568 16504 16503 16518>,
			<16753 16695 16593 16533 16537 16551>,
			<16782 16734 16630 16556 16550 16554>,
			<16790 16764 16649 16529 16487 16477>,
			<16768 16753 16641 16507 16470 16468>,
			<16768 16753 16679 16528 16475 16471>,
			<16965 16778 16741 16572 16497 16493>,
			<16965 16778 16741 16572 16497 16493>,
			<16965 16778 16741 16572 16497 16493>;
	};

	qcom,pc-temp-y5-lut {
		qcom,lut-col-legend = <(-10) 0 10 25 40 50>;
		qcom,lut-row-legend = <10000 9800 9600 9400 9200 9000>,
			<8800 8600 8400 8200 8000 7800>,
			<7600 7400 7200 7000 6800 6600>,
			<6400 6200 6000 5800 5600 5400>,
			<5200 5000 4800 4600 4400 4200>,
			<4000 3800 3600 3400 3200 3000>,
			<2800 2600 2400 2200 2000 1800>,
			<1600 1400 1200 1000 900 800>,
			<700 600 500 400 300 200>,
			<100 0>;
		qcom,lut-data = <11724 13686 17376 20638 17957 18663>,
			<12222 14082 17742 20156 18488 19034>,
			<12833 14720 18082 19678 18786 19230>,
			<13438 15416 18368 19210 18906 19295>,
			<13917 15983 18574 18754 18899 19271>,
			<14152 16235 18673 18313 18822 19201>,
			<14147 16222 18671 17826 18362 19039>,
			<14100 16186 18606 17391 17639 18760>,
			<14308 16273 18459 17273 17245 18377>,
			<15274 16691 18080 17561 17023 17742>,
			<15916 16961 17627 17612 16785 17236>,
			<15333 15644 17092 16943 16442 17009>,
			<14374 13536 16501 16124 16041 16824>,
			<15023 13555 16043 15814 15611 16522>,
			<20028 16260 15623 15683 15099 16018>,
			<23514 18560 15435 15570 14849 15748>,
			<21250 19357 16063 15415 15084 16059>,
			<17401 19938 17424 15288 15448 16526>,
			<16649 20247 19148 15462 15545 16481>,
			<17505 20462 21861 16509 15538 15856>,
			<18553 20585 23293 17967 15566 15472>,
			<19651 20411 22941 20825 17220 16541>,
			<20699 20113 22279 23687 19702 18339>,
			<20439 20455 21739 23602 20404 19250>,
			<17452 22412 21186 21548 20629 19833>,
			<14836 23753 20833 20054 20707 20069>,
			<13857 19860 20659 19463 20192 19760>,
			<13077 13350 20528 19071 19216 19110>,
			<12793 12050 20729 19210 18305 18313>,
			<12672 13205 21751 19932 17278 17148>,
			<12619 14095 22367 20545 16795 16559>,
			<12706 14977 20828 20850 16987 16623>,
			<12896 16414 18597 21151 17448 16795>,
			<13043 16986 18472 21769 18425 17449>,
			<13156 17708 19697 22822 20646 19580>,
			<13261 18193 20470 23300 21848 21121>,
			<13352 17035 20451 22970 21450 21493>,
			<13437 15014 20336 22379 20866 21761>,
			<13577 14561 20103 21807 20614 22397>,
			<13901 14706 19545 21165 20369 23598>,
			<14135 14812 19081 20448 20259 24211>,
			<13987 14678 18704 19410 21242 23440>,
			<13657 14390 18329 18912 22057 22597>,
			<13167 13965 17644 19282 19777 22476>,
			<12869 13839 17531 19431 19410 19923>,
			<12884 13994 17727 16949 18596 19518>,
			<12944 13758 17175 18298 17909 18082>,
			<13012 13927 17278 17805 17397 16820>,
			<13129 13905 17411 18811 17357 15911>,
			<13585 14285 17836 19031 16824 15697>,
			<13815 14358 17875 19310 17325 16852>,
			<13504 14333 15610 20122 18792 17266>,
			<13316 14003 14360 20816 20900 17818>,
			<12050 13575 14245 22050 23807 24813>,
			<12050 13575 14245 22050 23807 24813>,
			<12050 13575 14245 22050 23807 24813>;
	};

	qcom,pc-temp-y6-lut {
		qcom,lut-col-legend = <(-10) 0 10 25 40 50>;
		qcom,lut-row-legend = <10000 9800 9600 9400 9200 9000>,
			<8800 8600 8400 8200 8000 7800>,
			<7600 7400 7200 7000 6800 6600>,
			<6400 6200 6000 5800 5600 5400>,
			<5200 5000 4800 4600 4400 4200>,
			<4000 3800 3600 3400 3200 3000>,
			<2800 2600 2400 2200 2000 1800>,
			<1600 1400 1200 1000 900 800>,
			<700 600 500 400 300 200>,
			<100 0>;
		qcom,lut-data = <5667 5459 5206 5074 5040 5035>,
			<5669 5462 5204 5073 5040 5035>,
			<5669 5463 5202 5073 5040 5035>,
			<5668 5462 5200 5073 5041 5035>,
			<5667 5459 5198 5073 5041 5035>,
			<5665 5456 5196 5073 5041 5035>,
			<5662 5451 5194 5074 5042 5036>,
			<5659 5445 5191 5074 5042 5036>,
			<5655 5440 5190 5075 5043 5037>,
			<5651 5434 5189 5077 5044 5038>,
			<5650 5431 5189 5079 5045 5038>,
			<5655 5438 5189 5080 5046 5039>,
			<5665 5448 5190 5082 5048 5040>,
			<5665 5450 5193 5084 5049 5041>,
			<5656 5447 5201 5089 5052 5043>,
			<5642 5442 5209 5093 5054 5045>,
			<5621 5436 5213 5096 5056 5047>,
			<5598 5427 5216 5100 5058 5049>,
			<5594 5417 5216 5106 5063 5053>,
			<5595 5405 5208 5116 5072 5060>,
			<5596 5393 5198 5121 5077 5063>,
			<5594 5378 5180 5106 5067 5056>,
			<5589 5364 5160 5083 5051 5043>,
			<5583 5359 5152 5073 5044 5037>,
			<5574 5357 5148 5067 5040 5034>,
			<5569 5355 5147 5065 5038 5033>,
			<5573 5353 5147 5066 5038 5033>,
			<5583 5351 5147 5067 5039 5033>,
			<5593 5352 5148 5068 5040 5034>,
			<5604 5362 5149 5070 5041 5035>,
			<5616 5374 5150 5072 5043 5037>,
			<5630 5386 5150 5074 5046 5040>,
			<5644 5399 5151 5075 5049 5042>,
			<5660 5415 5152 5077 5050 5044>,
			<5675 5434 5159 5078 5051 5046>,
			<5693 5454 5167 5079 5051 5047>,
			<5711 5473 5173 5077 5047 5042>,
			<5730 5493 5180 5075 5040 5035>,
			<5752 5515 5185 5075 5039 5034>,
			<5775 5541 5190 5075 5041 5037>,
			<5799 5569 5196 5075 5042 5040>,
			<5825 5601 5205 5078 5046 5042>,
			<5853 5640 5218 5081 5048 5044>,
			<5893 5689 5233 5081 5042 5036>,
			<5952 5758 5258 5083 5041 5034>,
			<6007 5819 5266 5084 5045 5040>,
			<6049 5871 5284 5091 5051 5050>,
			<6110 5941 5311 5099 5063 5061>,
			<6185 6023 5341 5112 5075 5071>,
			<6280 6123 5382 5121 5078 5072>,
			<6388 6222 5414 5112 5057 5047>,
			<6529 6315 5445 5107 5053 5046>,
			<6784 6440 5538 5124 5059 5050>,
			<7555 6607 5683 5151 5070 5064>,
			<7555 6607 5683 5151 5070 5064>,
			<7555 6607 5683 5151 5070 5064>;
	};

};
